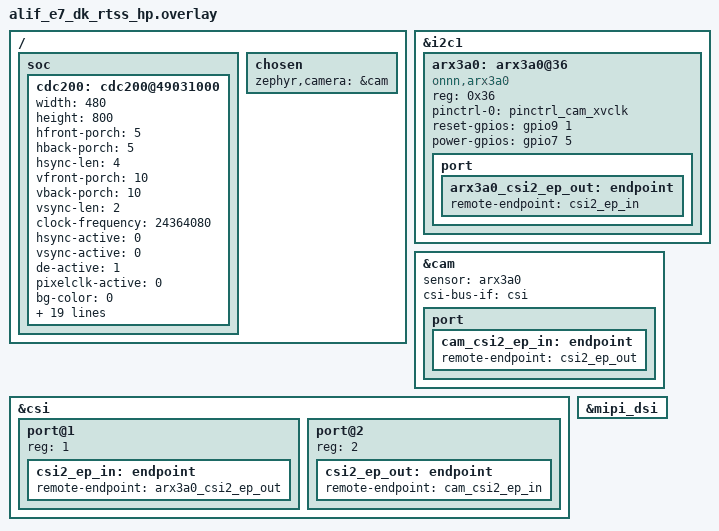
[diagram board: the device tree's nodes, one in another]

/ {
	soc {
		cdc200: cdc200@49031000 {
			width = <480>;
			height = <800>;
			hfront-porch = <5>;
			hback-porch = <5>;
			hsync-len = <4>;
			vfront-porch = <10>;
			vback-porch = <10>;
			vsync-len = <2>;
			clock-frequency = <24364080>;
			hsync-active = <0>;
			vsync-active = <0>;
			de-active = <1>;
			pixelclk-active = <0>;
			bg-color = <0>;
			enable-l1 = <1>;
			pixel-fmt-l1 = "rgb-888";
			def-back-color-l1 = <0>;
			win-x0-l1 = <0>;
			win-y0-l1 = <0>;
			win-x1-l1 = <480>;
			win-y1-l1 = <800>;
			blend-factor1-l1 = <4>;
			blend-factor2-l1 = <5>;
			const-alpha-l1 = <0xff>;
			enable-l2 = <0>;
			pixel-fmt-l2 = "undefined";
			win-x0-l2 = <0>;
			win-y0-l2 = <0>;
			win-x1-l2 = <0>;
			win-y1-l2 = <0>;
			blend-factor1-l2 = <6>;
			blend-factor2-l2 = <7>;
			const-alpha-l2 = <0xff>;
		};
	};
};

&i2c1 {
	status = "okay";

	arx3a0: arx3a0@36 {
		compatible = "onnn,arx3a0";
		reg = <0x36>;
		pinctrl-0 = < &pinctrl_cam_xvclk >;
		pinctrl-names = "default";
		reset-gpios = <&gpio9 1 GPIO_ACTIVE_HIGH>;
		power-gpios = <&gpio7 5 GPIO_ACTIVE_HIGH>;

		status = "okay";

		port {
			arx3a0_csi2_ep_out: endpoint {
				remote-endpoint = <&csi2_ep_in>;
			};
		};
	};
};

&cam {
	status = "okay";
	sensor = <&arx3a0>;
	csi-bus-if = <&csi>;
	port {
		/* MIPI CSI-2 bus endpoint. */
		cam_csi2_ep_in: endpoint {
			remote-endpoint = <&csi2_ep_out>;
		};
	};
};

&csi {
	#address-cells = <1>;
	#size-cells = <0>;
	port@1 {
		reg = <1>;
		csi2_ep_in: endpoint {
			remote-endpoint = <&arx3a0_csi2_ep_out>;
		};
	};
	port@2 {
		reg = <2>;
		csi2_ep_out: endpoint {
			remote-endpoint = <&cam_csi2_ep_in>;
		};
	};
};

&mipi_dsi {
	status = "okay";
};


/ {
	chosen {
		zephyr,camera = &cam;
	};
};
